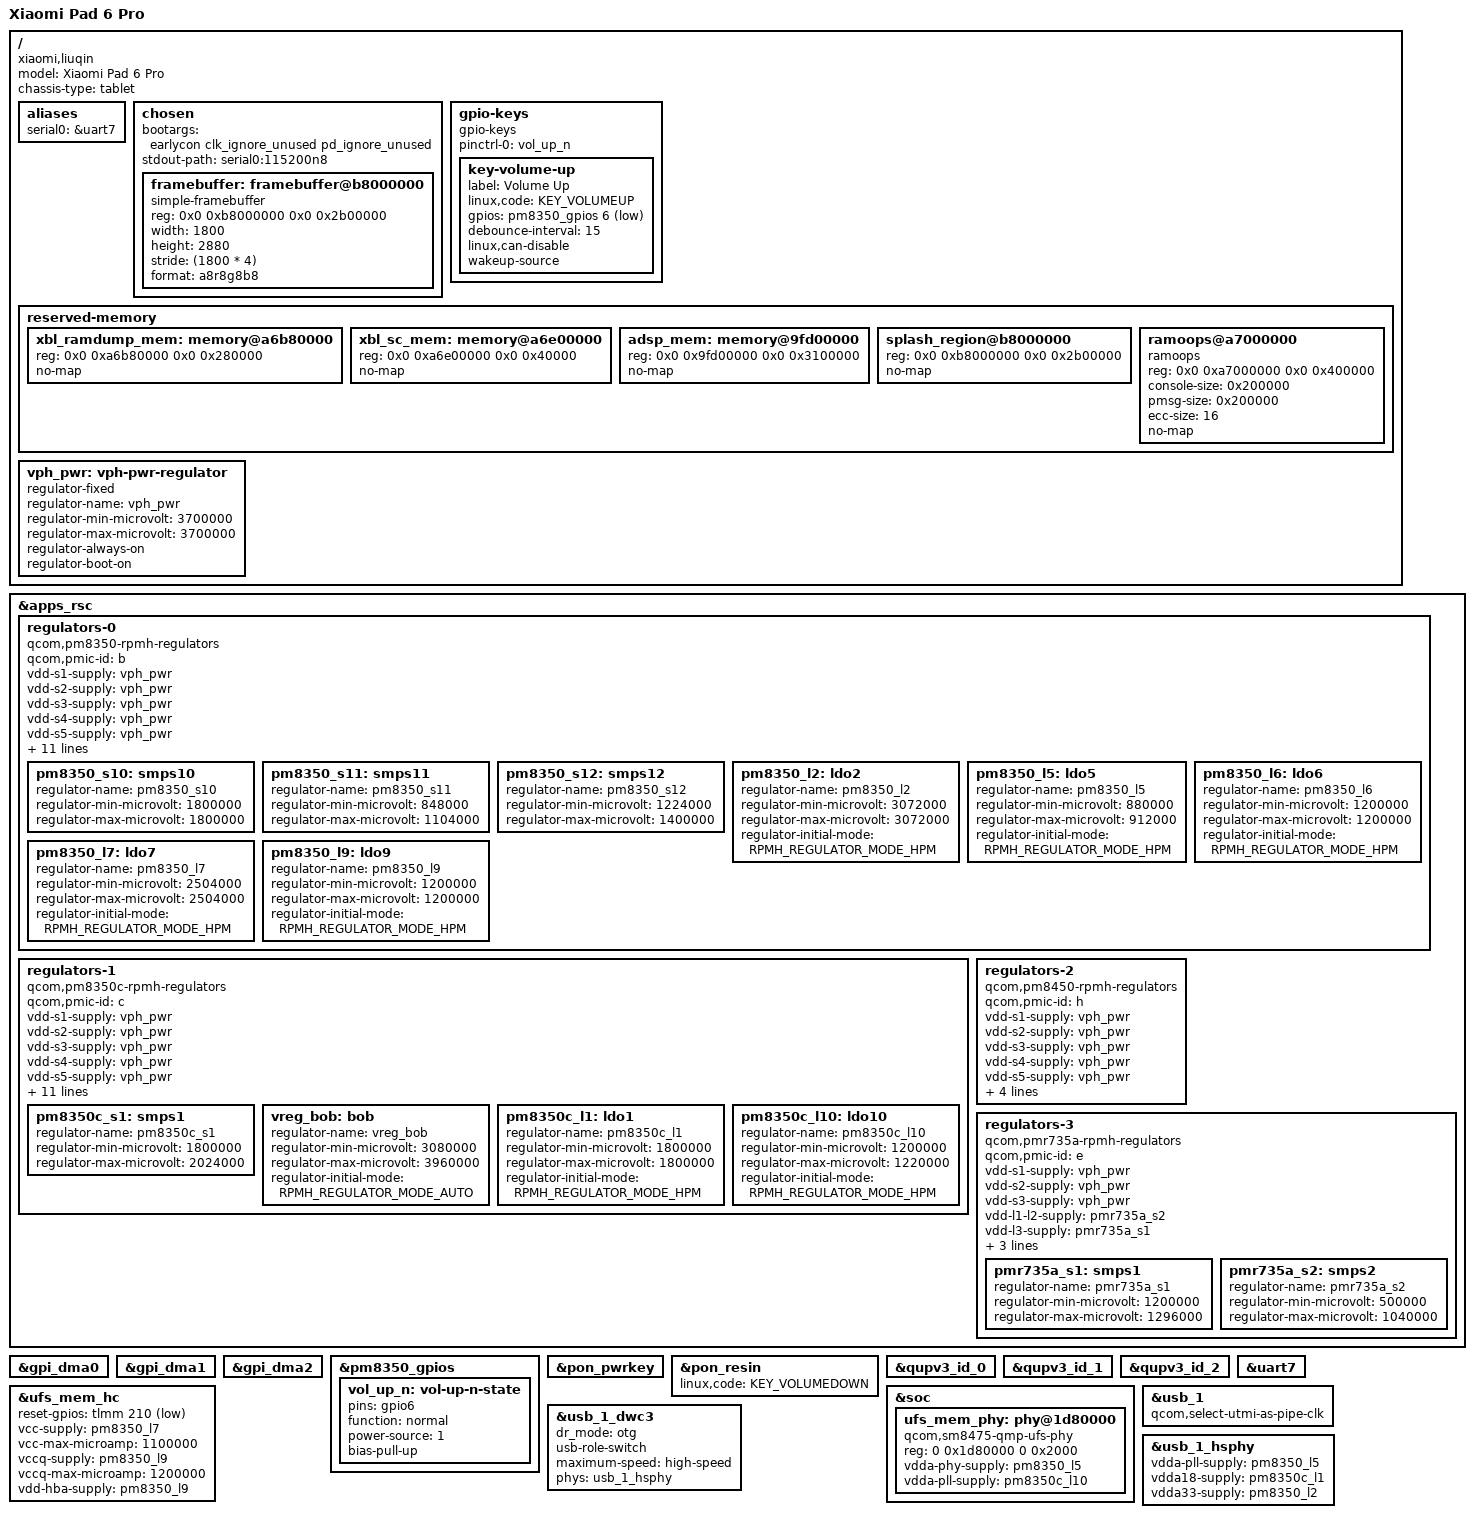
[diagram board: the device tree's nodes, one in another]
// SPDX-License-Identifier: GPL-2.0-only
/dts-v1/;

#include <dt-bindings/regulator/qcom,rpmh-regulator.h>
#include "sm8450.dtsi"
#include "pm8350.dtsi"
#include "pm8350b.dtsi"
#include "pm8350c.dtsi"
#include "pm8450.dtsi"
#include "pmk8350.dtsi"
#include "pmr735a.dtsi"

/* Regions owned by the stock boot chain / secure world; U-Boot must not touch them */
/delete-node/ &xbl_ramdump_mem;
/delete-node/ &xbl_sc_mem;
/delete-node/ &adsp_mem;
/delete-node/ &rmtfs_mem;
/delete-node/ &mte_mem;
/delete-node/ &trusted_apps_mem;
/delete-node/ &trusted_apps_ext_mem;

/*
 * SM8475 puts the UFS PHY at 0x1d80000, not at the SM8450 address
 * (0x1d87000) the upstream sm8450.dtsi describes, and it uses the v6
 * register window (COM 0, PCS 0x400, TX 0x1000, RX 0x1200) with its own
 * serdes tables. Confirmed against the stock bootloader DTB
 * (ufsphy_mem@1d80000, "qcom,ufs-phy-qmp-v4-cape") and the mainline
 * sm8475_ufsphy_cfg.
 */
/delete-node/ &ufs_mem_phy;

/ {
	model = "Xiaomi Pad 6 Pro";
	compatible = "xiaomi,liuqin", "qcom,sm8450";
	chassis-type = "tablet";

	aliases {
		serial0 = &uart7;
	};

	chosen {
		#address-cells = <2>;
		#size-cells = <2>;
		ranges;

		bootargs = "earlycon clk_ignore_unused pd_ignore_unused";
		stdout-path = "serial0:115200n8";

		/*
		 * ABL continuous-splash framebuffer, left scanning out at
		 * 0xb8000000 by the stock boot chain. Writing pixels here is
		 * enough to get a console; do NOT touch display clocks/power.
		 */
		framebuffer: framebuffer@b8000000 {
			compatible = "simple-framebuffer";
			reg = <0x0 0xb8000000 0x0 0x2b00000>;
			width = <1800>;
			height = <2880>;
			stride = <(1800 * 4)>;
			format = "a8r8g8b8";
		};
	};

	gpio-keys {
		compatible = "gpio-keys";

		pinctrl-0 = <&vol_up_n>;
		pinctrl-names = "default";

		key-volume-up {
			label = "Volume Up";
			linux,code = <KEY_VOLUMEUP>;
			gpios = <&pm8350_gpios 6 GPIO_ACTIVE_LOW>;
			debounce-interval = <15>;
			linux,can-disable;
			wakeup-source;
		};
	};

	reserved-memory {
		xbl_ramdump_mem: memory@a6b80000 {
			reg = <0x0 0xa6b80000 0x0 0x280000>;
			no-map;
		};

		xbl_sc_mem: memory@a6e00000 {
			reg = <0x0 0xa6e00000 0x0 0x40000>;
			no-map;
		};

		adsp_mem: memory@9fd00000 {
			reg = <0x0 0x9fd00000 0x0 0x3100000>;
			no-map;
		};

		splash_region@b8000000 {
			reg = <0x0 0xb8000000 0x0 0x2b00000>;
			no-map;
		};

		ramoops@a7000000 {
			compatible = "ramoops";
			reg = <0x0 0xa7000000 0x0 0x400000>;
			console-size = <0x200000>;
			pmsg-size = <0x200000>;
			ecc-size = <16>;
			no-map;
		};
	};

	vph_pwr: vph-pwr-regulator {
		compatible = "regulator-fixed";
		regulator-name = "vph_pwr";
		regulator-min-microvolt = <3700000>;
		regulator-max-microvolt = <3700000>;

		regulator-always-on;
		regulator-boot-on;
	};
};

&apps_rsc {
	regulators-0 {
		compatible = "qcom,pm8350-rpmh-regulators";
		qcom,pmic-id = "b";

		vdd-s1-supply = <&vph_pwr>;
		vdd-s2-supply = <&vph_pwr>;
		vdd-s3-supply = <&vph_pwr>;
		vdd-s4-supply = <&vph_pwr>;
		vdd-s5-supply = <&vph_pwr>;
		vdd-s6-supply = <&vph_pwr>;
		vdd-s7-supply = <&vph_pwr>;
		vdd-s8-supply = <&vph_pwr>;
		vdd-s9-supply = <&vph_pwr>;
		vdd-s10-supply = <&vph_pwr>;
		vdd-s11-supply = <&vph_pwr>;
		vdd-s12-supply = <&vph_pwr>;

		vdd-l1-l4-supply = <&pm8350_s11>;
		vdd-l2-l7-supply = <&vreg_bob>;
		vdd-l3-l5-supply = <&pm8350_s11>;
		vdd-l6-l9-l10-supply = <&pm8350_s12>;

		pm8350_s10: smps10 {
			regulator-name = "pm8350_s10";
			regulator-min-microvolt = <1800000>;
			regulator-max-microvolt = <1800000>;
		};

		pm8350_s11: smps11 {
			regulator-name = "pm8350_s11";
			regulator-min-microvolt = <848000>;
			regulator-max-microvolt = <1104000>;
		};

		pm8350_s12: smps12 {
			regulator-name = "pm8350_s12";
			regulator-min-microvolt = <1224000>;
			regulator-max-microvolt = <1400000>;
		};

		pm8350_l2: ldo2 {
			regulator-name = "pm8350_l2";
			regulator-min-microvolt = <3072000>;
			regulator-max-microvolt = <3072000>;
			regulator-initial-mode = <RPMH_REGULATOR_MODE_HPM>;
		};

		pm8350_l5: ldo5 {
			regulator-name = "pm8350_l5";
			regulator-min-microvolt = <880000>;
			regulator-max-microvolt = <912000>;
			regulator-initial-mode = <RPMH_REGULATOR_MODE_HPM>;
		};

		pm8350_l6: ldo6 {
			regulator-name = "pm8350_l6";
			regulator-min-microvolt = <1200000>;
			regulator-max-microvolt = <1200000>;
			regulator-initial-mode = <RPMH_REGULATOR_MODE_HPM>;
		};

		pm8350_l7: ldo7 {
			regulator-name = "pm8350_l7";
			regulator-min-microvolt = <2504000>;
			regulator-max-microvolt = <2504000>;
			regulator-initial-mode = <RPMH_REGULATOR_MODE_HPM>;
		};

		pm8350_l9: ldo9 {
			regulator-name = "pm8350_l9";
			regulator-min-microvolt = <1200000>;
			regulator-max-microvolt = <1200000>;
			regulator-initial-mode = <RPMH_REGULATOR_MODE_HPM>;
		};
	};

	regulators-1 {
		compatible = "qcom,pm8350c-rpmh-regulators";
		qcom,pmic-id = "c";

		vdd-s1-supply = <&vph_pwr>;
		vdd-s2-supply = <&vph_pwr>;
		vdd-s3-supply = <&vph_pwr>;
		vdd-s4-supply = <&vph_pwr>;
		vdd-s5-supply = <&vph_pwr>;
		vdd-s6-supply = <&vph_pwr>;
		vdd-s7-supply = <&vph_pwr>;
		vdd-s8-supply = <&vph_pwr>;
		vdd-s9-supply = <&vph_pwr>;
		vdd-s10-supply = <&vph_pwr>;

		vdd-l1-l12-supply = <&pm8350c_s1>;
		vdd-l2-l8-supply = <&pm8350c_s1>;
		vdd-l3-l4-l5-l7-l13-supply = <&vreg_bob>;
		vdd-l6-l9-l11-supply = <&vreg_bob>;
		vdd-l10-supply = <&pm8350_s12>;

		vdd-bob-supply = <&vph_pwr>;

		pm8350c_s1: smps1 {
			regulator-name = "pm8350c_s1";
			regulator-min-microvolt = <1800000>;
			regulator-max-microvolt = <2024000>;
		};

		vreg_bob: bob {
			regulator-name = "vreg_bob";
			regulator-min-microvolt = <3080000>;
			regulator-max-microvolt = <3960000>;
			regulator-initial-mode = <RPMH_REGULATOR_MODE_AUTO>;
		};

		pm8350c_l1: ldo1 {
			regulator-name = "pm8350c_l1";
			regulator-min-microvolt = <1800000>;
			regulator-max-microvolt = <1800000>;
			regulator-initial-mode = <RPMH_REGULATOR_MODE_HPM>;
		};

		pm8350c_l10: ldo10 {
			regulator-name = "pm8350c_l10";
			regulator-min-microvolt = <1200000>;
			regulator-max-microvolt = <1220000>;
			regulator-initial-mode = <RPMH_REGULATOR_MODE_HPM>;
		};
	};

	regulators-2 {
		compatible = "qcom,pm8450-rpmh-regulators";
		qcom,pmic-id = "h";

		vdd-s1-supply = <&vph_pwr>;
		vdd-s2-supply = <&vph_pwr>;
		vdd-s3-supply = <&vph_pwr>;
		vdd-s4-supply = <&vph_pwr>;
		vdd-s5-supply = <&vph_pwr>;
		vdd-s6-supply = <&vph_pwr>;

		vdd-l2-supply = <&vreg_bob>;
		vdd-l3-supply = <&vreg_bob>;
		vdd-l4-supply = <&vreg_bob>;
	};

	regulators-3 {
		compatible = "qcom,pmr735a-rpmh-regulators";
		qcom,pmic-id = "e";

		vdd-s1-supply = <&vph_pwr>;
		vdd-s2-supply = <&vph_pwr>;
		vdd-s3-supply = <&vph_pwr>;

		vdd-l1-l2-supply = <&pmr735a_s2>;
		vdd-l3-supply = <&pmr735a_s1>;
		vdd-l4-supply = <&pm8350c_s1>;
		vdd-l5-l6-supply = <&pm8350c_s1>;
		vdd-l7-bob-supply = <&vreg_bob>;

		pmr735a_s1: smps1 {
			regulator-name = "pmr735a_s1";
			regulator-min-microvolt = <1200000>;
			regulator-max-microvolt = <1296000>;
		};

		pmr735a_s2: smps2 {
			regulator-name = "pmr735a_s2";
			regulator-min-microvolt = <500000>;
			regulator-max-microvolt = <1040000>;
		};
	};
};

&gpi_dma0 {
	status = "okay";
};

&gpi_dma1 {
	status = "okay";
};

&gpi_dma2 {
	status = "okay";
};

&pm8350_gpios {
	vol_up_n: vol-up-n-state {
		pins = "gpio6";
		function = "normal";
		power-source = <1>;
		bias-pull-up;
	};
};

&pon_pwrkey {
	status = "okay";
};

&pon_resin {
	linux,code = <KEY_VOLUMEDOWN>;
	status = "okay";
};

&qupv3_id_0 {
	status = "okay";
};

&qupv3_id_1 {
	status = "okay";
};

&qupv3_id_2 {
	status = "okay";
};

/* GENI UART debug console, SE7 @ 0x99c000 (GPIO26/27) */
&uart7 {
	status = "okay";
};

/* UFS: controller @ 0x1d84000, QMP v4 PHY @ 0x1d80000, PM8350 rails */
&ufs_mem_hc {
	status = "okay";

	reset-gpios = <&tlmm 210 GPIO_ACTIVE_LOW>;

	vcc-supply = <&pm8350_l7>;
	vcc-max-microamp = <1100000>;
	vccq-supply = <&pm8350_l9>;
	vccq-max-microamp = <1200000>;
	vdd-hba-supply = <&pm8350_l9>;
};

&soc {
	ufs_mem_phy: phy@1d80000 {
		compatible = "qcom,sm8475-qmp-ufs-phy";
		reg = <0 0x1d80000 0 0x2000>;
		#phy-cells = <0>;
		#clock-cells = <1>;

		status = "okay";

		vdda-phy-supply = <&pm8350_l5>;
		vdda-pll-supply = <&pm8350c_l10>;
	};
};

/* Single USB 2.0 port */
&usb_1 {
	qcom,select-utmi-as-pipe-clk;
	status = "okay";
};

&usb_1_dwc3 {
	dr_mode = "otg";
	usb-role-switch;
	maximum-speed = "high-speed";
	phys = <&usb_1_hsphy>;
	phy-names = "usb2-phy";
};

&usb_1_hsphy {
	vdda-pll-supply = <&pm8350_l5>;
	vdda18-supply = <&pm8350c_l1>;
	vdda33-supply = <&pm8350_l2>;

	status = "okay";
};
